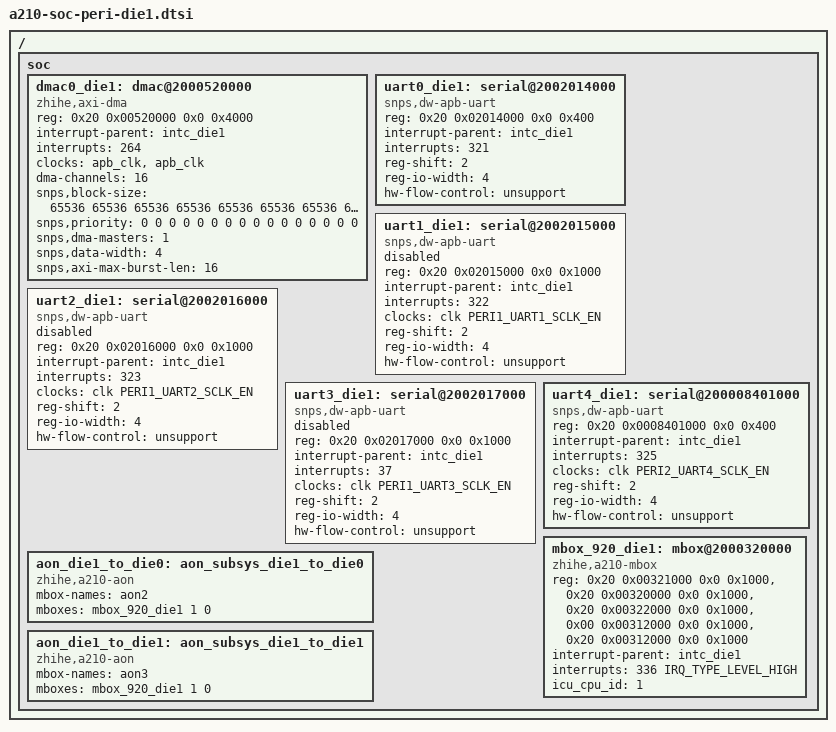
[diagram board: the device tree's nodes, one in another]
#include <dt-bindings/interrupt-controller/irq.h>
#include <dt-bindings/clock/a210-clock.h>

/ {
	soc {
		dmac0_die1: dmac@2000520000 {
			compatible = "zhihe,axi-dma";
			reg = <0x20 0x00520000 0x0 0x4000>;
			interrupt-parent = <&intc_die1>;
			interrupts = <264>;
			clocks = <&apb_clk>, <&apb_clk>;
			clock-names = "core-clk", "cfgr-clk";
			#dma-cells = <1>;
			dma-channels = <16>;
			snps,block-size = <65536 65536 65536 65536 65536 65536 65536 65536
								65536 65536 65536 65536 65536 65536 65536 65536>;
			snps,priority = <0 0 0 0 0 0 0 0 0 0 0 0 0 0 0 0>;
			snps,dma-masters = <1>;
			snps,data-width = <4>;
			snps,axi-max-burst-len = <16>;
			status = "okay";
		};

		uart0_die1: serial@2002014000 {
			compatible = "snps,dw-apb-uart", "ns16550";
			reg = <0x20 0x02014000 0x0 0x400>;
			interrupt-parent = <&intc_die1>;
			interrupts = <321>;
			clock-names = "baudclk";
			reg-shift = <2>;
			reg-io-width = <4>;
			hw-flow-control = "unsupport";
			status = "okay";
		};

		uart1_die1: serial@2002015000 {
			compatible = "snps,dw-apb-uart";
			reg = <0x20 0x02015000 0x0 0x1000>;
			interrupt-parent = <&intc_die1>;
			interrupts = <322>;
			clocks = <&clk PERI1_UART1_SCLK_EN>;
			clock-names = "baudclk";
			reg-shift = <2>;
			reg-io-width = <4>;
			hw-flow-control = "unsupport";
			status = "disabled";
		};

		uart2_die1: serial@2002016000 {
			compatible = "snps,dw-apb-uart";
			reg = <0x20 0x02016000 0x0 0x1000>;
			interrupt-parent = <&intc_die1>;
			interrupts = <323>;
			clocks = <&clk PERI1_UART2_SCLK_EN>;
			clock-names = "baudclk";
			reg-shift = <2>;
			reg-io-width = <4>;
			hw-flow-control = "unsupport";
			status = "disabled";
		};

		uart3_die1: serial@2002017000 {
			compatible = "snps,dw-apb-uart";
			reg = <0x20 0x02017000 0x0 0x1000>;
			interrupt-parent = <&intc_die1>;
			interrupts = <37>;
			clocks = <&clk PERI1_UART3_SCLK_EN>;
			clock-names = "baudclk";
			reg-shift = <2>;
			reg-io-width = <4>;
			hw-flow-control = "unsupport";
			status = "disabled";
		};

		uart4_die1: serial@200008401000 {
			compatible = "snps,dw-apb-uart";
			reg = <0x20 0x0008401000 0x0 0x400>;
			interrupt-parent = <&intc_die1>;
			interrupts = <325>;
			clocks = <&clk PERI2_UART4_SCLK_EN>;
			clock-names = "baudclk";
			reg-shift = <2>;
			reg-io-width = <4>;
			hw-flow-control = "unsupport";
			status = "okay";
		};
		mbox_920_die1: mbox@2000320000 {
                        compatible = "zhihe,a210-mbox";
			reg = <0x20 0x00321000 0x0 0x1000>,        //mailbox1的中断通道
			      <0x20 0x00320000 0x0 0x1000>,
			      <0x20 0x00322000 0x0 0x1000>,
			      <0x00 0x00312000 0x0 0x1000>,
			      <0x20 0x00312000 0x0 0x1000>;
			reg-names = "interrupt_addr",
				    "local_addr0",
				    "local_addr1",
				    "remote_icu0",
				    "remote_icu1";
			interrupt-parent = <&intc_die1>;
			interrupts = <336 IRQ_TYPE_LEVEL_HIGH>;
			icu_cpu_id = <1>;
			#mbox-cells = <2>;
			status = "okay";
		};
		aon_die1_to_die0: aon_subsys_die1_to_die0 {
			compatible = "zhihe,a210-aon";
			mbox-names = "aon2";
			mboxes = <&mbox_920_die1 1 0>;                     //parent / channel / type
			#mbox-cells = <2>;
			status = "okay";
		};
		aon_die1_to_die1: aon_subsys_die1_to_die1 {
			compatible = "zhihe,a210-aon";
			mbox-names = "aon3";
			mboxes = <&mbox_920_die1 1 0>;
			#mbox-cells = <2>;
			status = "okay";
		};
	};
};
